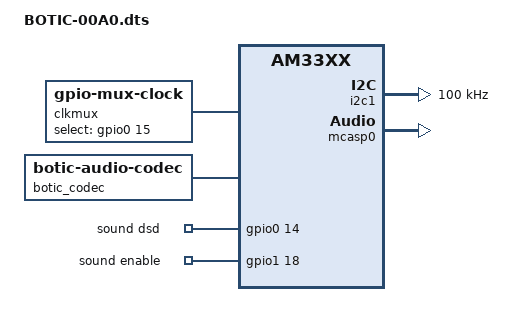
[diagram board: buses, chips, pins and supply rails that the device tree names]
/*
 * Copyright (C) 2012 Texas Instruments Incorporated - http://www.ti.com/
 *
 * This program is free software; you can redistribute it and/or modify
 * it under the terms of the GNU General Public License version 2 as
 * published by the Free Software Foundation.
 */
/dts-v1/;
/plugin/;

#include <dt-bindings/board/am335x-bbw-bbb-base.h>
#include <dt-bindings/gpio/gpio.h>
#include <dt-bindings/pinctrl/am33xx.h>

/ {
	compatible = "ti,am335x-bone-black-wireless", "ti,am335x-bone-black", "ti,am335x-bone", "ti,am33xx";

	/* identification */
	part-number = "BOTIC";
	version = "00A0";

	/* state the resources this cape uses */
	exclusive-use =
		"P9.17",	/* i2c1_scl */
		"P9.18",	/* i2c1_sda */
		/* the pin header uses */
		"P9.25",	/* mcasp0_ahclkx (oscillator) */
		"P9.31",	/* mcaps0_aclkx (bit clock) */
		"P9.29",	/* mcasp0_fsx (lr clock) */
		"P9.30",	/* mcasp0_axr0 (data0) */
		"P9.41",	/* mcasp0_axr1 (data1) */
		"P9.42",	/* mcasp0_axr2 (data2) pinconfig=default */
		"P9.27",	/* mcasp0_axr3 (data3) */
		"P9.24",	/* uart1_txd (external masterclock switch) */
		"P9.26",	/* uart1_rxd (I2S/DSD format switch) */
		"P9.14",	/* gpmc_a2 (cape power switch) */
		/* the hardware IP uses */
		"i2c1",
		"mcasp0";

	fragment@0 {
		target = <&cpu0_opp_table>;
		__overlay__ {
			oppnitro-1000000000 {
				opp-supported-hw = <0x06 0x0100>;
			};
		};
	};
	

	fragment@1 {
		target = <&am33xx_pinmux>;
		__overlay__ {
			/* Overwrite the default pinctrl for the pinmux, this makes the pin usable for MCASP */
			pinctrl-names = "default";
			pinctrl-0 = <&clkout2_custom_pin>;

			botic_cape_pins: botic_cape_pins {
				pinctrl-single,pins = <
					/* onboard 24.576MHz oscillator control */
					AM33XX_IOPAD(0x86c, PIN_OUTPUT_PULLDOWN | MUX_MODE7)	/* gpmc_a11.GPIO1_27 */
					/* external masterclock enable */
					AM33XX_IOPAD(0x848, PIN_OUTPUT_PULLDOWN | MUX_MODE7)    /* gpmc_a2.gpio1_18 */
					/* external masterclock switch */
					AM33XX_IOPAD(0x984, PIN_OUTPUT_PULLDOWN | MUX_MODE7)    /* uart1_txd.gpio0_15 */
					/* DSD format switch */
					AM33XX_IOPAD(0x980, PIN_OUTPUT_PULLDOWN | MUX_MODE7)    /* uart1_rxd.gpio0_14 */
				>;
			};

			clkout2_custom_pin: pinmux_clkout2_custom_pin {
				pinctrl-single,pins = <

					AM33XX_IOPAD(0x9b4, PIN_INPUT | MUX_MODE7)
				>;
			};

			mcasp0_custom_pins: mcasp0_custom_pins {
				pinctrl-single,pins = <
					/* bitclock */
					AM33XX_IOPAD(0x990, PIN_OUTPUT | MUX_MODE0)	/* mcasp0_aclkx.mcasp0_aclkx */
					/* wordclock */
					AM33XX_IOPAD(0x994, PIN_OUTPUT | MUX_MODE0)	/* mcasp0_fsx.mcasp0_fsx */
					/* data pins */
					AM33XX_IOPAD(0x998, PIN_OUTPUT | MUX_MODE0)	/* mcasp0_axr0.mcasp0_axr0 */
					AM33XX_IOPAD(0x9a8, PIN_OUTPUT | MUX_MODE0)    /* mcasp0_axr1 */
					/* disable eCAP0_in_PWM0_out to allow usage of mcasp0_axr2 on P9_42 */
					AM33XX_IOPAD(0x964, PIN_INPUT | MUX_MODE7)              /* ecap0_in_pwm0_out.gpio0_7 */
					AM33XX_IOPAD(0x9a0, PIN_OUTPUT | MUX_MODE2)	/* mcasp0_aclkr.mcasp0_axr2 */
					AM33XX_IOPAD(0x9a4, PIN_OUTPUT | MUX_MODE2)    /* mcasp0_fsr.mcasp0_axr3 */
					/* master clock */
					AM33XX_IOPAD(0x9ac, PIN_INPUT | MUX_MODE0)	/* MCASP0_AHCLKX -> MCASP0_AHCLKX (I2S_MCLK_OUT)- in */
					
				>;
			};
			
			i2c1_pins: pinmux_bb_i2c1_pins {
				pinctrl-single,pins = <
					AM33XX_IOPAD(0x958, PIN_INPUT_PULLUP | SLEWCTRL_SLOW | MUX_MODE2)
					AM33XX_IOPAD(0x95c, PIN_INPUT_PULLUP | SLEWCTRL_SLOW | MUX_MODE2)
				>;
			};
		};
	};

	fragment@2 {
		target-path="/";

		__overlay__ {

       			clk48: clk48 {
				#clock-cells = <0>;
				compatible = "fixed-clock";
				clock-frequency = <49152000>;
			};

			clk44: clk44 {
				#clock-cells = <0>;
				compatible = "fixed-clock";
				clock-frequency = <45158400>;
			};

			clkmux: clkmux {
				#clock-cells = <0>;
				compatible = "gpio-mux-clock";
				clocks = <&clk44>, <&clk48>;
				select-gpios = <&gpio0 15 0>;
			};

			botic_codec: botic_codec {
				compatible = "botic-audio-codec";
				status = "okay";
			};

			sound {
				compatible = "botic-audio-card";
				status = "okay";

				pinctrl-names = "default";
				pinctrl-0 = <&botic_cape_pins>;

				clocks = <&clkmux>, <&clk48>, <&clk44>;
				clock-names = "mux", "clk48", "clk44";

				audio-port = <&mcasp0>;
				audio-codec = <&botic_codec>;
				audio-codec-dai = "botic-hifi";

				dsd-gpios = <&gpio0 14 0>;
				enable-gpios = <&gpio1 18 0>;
			};
		};
	};
	
	/* (Hermes-BBB) The I2C1 for isolated I2C access. */
	fragment@3 {
		target = <&i2c1>;
		__overlay__ {
			#address-cells = <1>;
			#size-cells = <0>;
			status = "okay";
			pinctrl-names = "default";
			pinctrl-0 = <&i2c1_pins>;
			clock-frequency = <100000>;
		};
	};
	
	/* Enable and configure McASP as needed. */
	fragment@4 {
		target = <&mcasp0>;
		__overlay__ {
			pinctrl-names = "default";
			status = "okay";
			pinctrl-0 = <&mcasp0_custom_pins>;
			serial-dir = <  /* 0: INACTIVE, 1: TX, 2: RX */
				1 1 1 1
			>;
			tx-num-evt = <32>;
			rx-num-evt = <32>;
		};
	};
};
